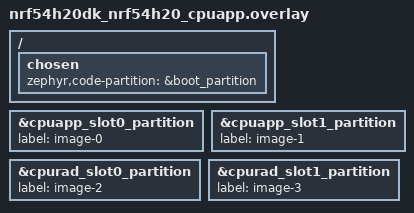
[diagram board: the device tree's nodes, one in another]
/*
 * Copyright (c) 2025 Nordic Semiconductor ASA
 *
 * SPDX-License-Identifier: LicenseRef-Nordic-5-Clause
 */

#include "../../nrf54h20dk_nrf54h20_memory_map.dtsi"

/ {
	chosen {
		zephyr,code-partition = &boot_partition;
	};
};

slot0_partition: &cpuapp_slot0_partition {
	label = "image-0";
};

slot1_partition: &cpuapp_slot1_partition {
	label = "image-1";
};

slot2_partition: &cpurad_slot0_partition {
	label = "image-2";
};

slot3_partition: &cpurad_slot1_partition {
	label = "image-3";
};
